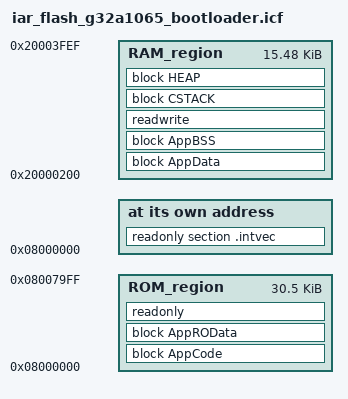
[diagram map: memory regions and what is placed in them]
/*###ICF### Section handled by ICF editor, don't touch! ****/
/*-Editor annotation file-*/
/* IcfEditorFile="$TOOLKIT_DIR$\config\ide\IcfEditor\cortex_v1_0.xml" */
/*-Specials-*/
define symbol __ICFEDIT_intvec_start__ = 0x08000000;
/*-Memory Regions-*/
define symbol __ICFEDIT_region_ROM_start__ = 0x08000000;
define symbol __ICFEDIT_region_ROM_end__   = 0x080079FF;
define symbol __ICFEDIT_region_RAM_flash_driver_start__ = 0x20000000;
define symbol __ICFEDIT_region_RAM_flash_driver_end__ = 0x200001FF;
define symbol __ICFEDIT_region_RAM_start__   = 0x20000200;
define symbol __ICFEDIT_region_RAM_end__   = 0x20003FEF;
/*-Sizes-*/
define symbol __ICFEDIT_size_cstack__ = 0x800;
define symbol __ICFEDIT_size_heap__   = 0x800;
/**** End of ICF editor section. ###ICF###*/

define memory mem with size = 4G;
define region ROM_region   = mem:[from __ICFEDIT_region_ROM_start__   to __ICFEDIT_region_ROM_end__];
define region RAM_region   = mem:[from __ICFEDIT_region_RAM_start__   to __ICFEDIT_region_RAM_end__];

define block CSTACK    with alignment = 8, size = __ICFEDIT_size_cstack__   { };
define block HEAP      with alignment = 8, size = __ICFEDIT_size_heap__     { };
define block AppCode with fixed order           { section .text, section .mcal_text};
define block AppROData with fixed order         { section .rodata,  section .mcal_const_cfg, section .mcal_const};
define block AppData with fixed order           { section .data, section .mcal_data, section .ramcode };
define block AppBSS with fixed order            { section .noinit, section .bss, section .mcal_bss};

initialize by copy { readwrite, section .data, section .mcal_data, section .ramcode };

place at address mem:__ICFEDIT_intvec_start__ { readonly section .intvec };

place in ROM_region   { block AppCode, block AppROData, readonly };
place in RAM_region   { block AppData, block AppBSS, readwrite,
                        block CSTACK, block HEAP };

export symbol __ICFEDIT_region_RAM_start__;
export symbol __ICFEDIT_region_RAM_end__;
